AUTOSAR XML (schema 4-3-0)
standard types defined: boolean, uint8, boolean_CompuMethod, boolean_DataConstr, uint8_DataConstr
package /ComponentTypes/HkmcDiagSWC
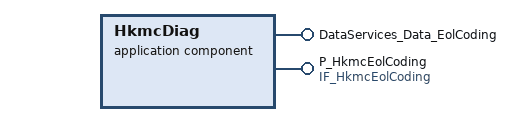
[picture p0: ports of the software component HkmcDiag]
  application sw component type HkmcDiag
    provide port DataServices_Data_EolCoding: provided-interface=DataServices_Data_EolCoding
      provided-com-specs:
        operation=ConditionCheckRead, queue-length=1
        operation=ReadData, queue-length=1
        operation=WriteData, queue-length=1
    provide port P_HkmcEolCoding: provided-com-specs=[{operation=HkmcEolCodingRead, queue-length=1}, {operation=HkmcEolCodingWrite, queue-length=1}], provided-interface=IF_HkmcEolCoding
    behavior HkmcDiag_InternalBehavior
      operation invoked event OIT_DataServices_Data_EolCoding_ConditionCheckRead_DataServices_Data_EolCoding_ConditionCheckRead: start-on-event=DataServices_Data_EolCoding_ConditionCheckRead, operation=DataServices_Data_EolCoding.ConditionCheckRead
      operation invoked event OIT_DataServices_Data_EolCoding_ReadData_DataServices_Data_EolCoding_ReadData: start-on-event=DataServices_Data_EolCoding_ReadData, operation=DataServices_Data_EolCoding.ReadData
      operation invoked event OIT_DataServices_Data_EolCoding_WriteData_DataServices_Data_EolCoding_WriteData: start-on-event=DataServices_Data_EolCoding_WriteData, operation=DataServices_Data_EolCoding.WriteData
      init event HkmcDiag_InitEvent: start-on-event=HkmcDiag_Init
      operation invoked event OIT_P_HkmcEolCoding_HkmcEolCodingRead_P_HkmcEolCoding_HkmcEolCodingRead: start-on-event=P_HkmcEolCoding_HkmcEolCodingRead, operation=P_HkmcEolCoding.HkmcEolCodingRead
      operation invoked event OIT_P_HkmcEolCoding_HkmcEolCodingWrite_P_HkmcEolCoding_HkmcEolCodingWrite: start-on-event=P_HkmcEolCoding_HkmcEolCodingWrite, operation=P_HkmcEolCoding.HkmcEolCodingWrite
      6 x runnable:
        DataServices_Data_EolCoding_ConditionCheckRead
        DataServices_Data_EolCoding_ReadData
        DataServices_Data_EolCoding_WriteData
        HkmcDiag_Init
        P_HkmcEolCoding_HkmcEolCodingRead
        P_HkmcEolCoding_HkmcEolCodingWrite
  swc implementation HkmcDiag_Implementation: behavior=HkmcDiag_InternalBehavior
    code-descriptors:
      code Default: artifact-descriptors=autosar-engineering-object={short-label=Default, category=SWSRC}
package /ComponentTypes/HkmcDiagSWC/DataTypes
  impl type HkmcEolData: category=STRUCTURE, type-emitter=RTE
    8 x element, all with category=TYPE_REFERENCE, implementation-data-type=uint8:
      data{1..8}
package /ComponentTypes/HkmcDiagSWC/PortInterfaces
  client server interface IF_HkmcEolCoding: is-service=true
    operation HkmcEolCodingRead
      arg EolDataIn: type=HkmcEolData, direction=IN, server-argument-impl-policy=USE-ARGUMENT-TYPE
      arg ReadStatus: type=boolean, direction=OUT, server-argument-impl-policy=USE-ARGUMENT-TYPE
    operation HkmcEolCodingWrite
      arg EolDataIn: type=HkmcEolData, direction=IN, server-argument-impl-policy=USE-ARGUMENT-TYPE
      arg WriteStatus: type=boolean, direction=OUT, server-argument-impl-policy=USE-ARGUMENT-TYPE
package /MICROSAR/Dcm_swc/DataTypes
  impl type Dcm_Data8ByteType: category=ARRAY, sw-calibration-access=READ-ONLY
    element Dcm_Data8ByteTypeElement: array-size=8, array-size-semantics=FIXED-SIZE, implementation-data-type=uint8
  impl type Dcm_NegativeResponseCodeType:
    compu {0=DCM_E_POSITIVERESPONSE, 16=DCM_E_GENERALREJECT, 17=DCM_E_SERVICENOTSUPPORTED, 18=DCM_E_SUBFUNCTIONNOTSUPPORTED, 19=DCM_E_INCORRECTMESSAGELENGTHORINVALIDFORMAT, 20=DCM_E_RESPONSETOOLONG, 33=DCM_E_BUSYREPEATREQUEST, 34=DCM_E_CONDITIONSNOTCORRECT, 36=DCM_E_REQUESTSEQUENCEERROR, 37=DCM_E_NORESPONSEFROMSUBNETCOMPONENT, 38=DCM_E_FAILUREPREVENTSEXECUTIONOFREQUESTEDACTION, 49=DCM_E_REQUESTOUTOFRANGE, 51=DCM_E_SECURITYACCESSDENIED, 53=DCM_E_INVALIDKEY, 54=DCM_E_EXCEEDNUMBEROFATTEMPTS, 55=DCM_E_REQUIREDTIMEDELAYNOTEXPIRED, 112=DCM_E_UPLOADDOWNLOADNOTACCEPTED, 113=DCM_E_TRANSFERDATASUSPENDED, 114=DCM_E_GENERALPROGRAMMINGFAILURE, 115=DCM_E_WRONGBLOCKSEQUENCECOUNTER, 120=DCM_E_REQUESTCORRECTLYRECEIVEDRESPONSEPENDING, 126=DCM_E_SUBFUNCTIONNOTSUPPORTEDINACTIVESESSION, 127=DCM_E_SERVICENOTSUPPORTEDINACTIVESESSION, 129=DCM_E_RPMTOOHIGH, 130=DCM_E_RPMTOOLOW, 131=DCM_E_ENGINEISRUNNING, 132=DCM_E_ENGINEISNOTRUNNING, 133=DCM_E_ENGINERUNTIMETOOLOW, 134=DCM_E_TEMPERATURETOOHIGH, 135=DCM_E_TEMPERATURETOOLOW, 136=DCM_E_VEHICLESPEEDTOOHIGH, 137=DCM_E_VEHICLESPEEDTOOLOW, 138=DCM_E_THROTTLE_PEDALTOOHIGH, 139=DCM_E_THROTTLE_PEDALTOOLOW, 140=DCM_E_TRANSMISSIONRANGENOTINNEUTRAL, 141=DCM_E_TRANSMISSIONRANGENOTINGEAR, 143=DCM_E_BRAKESWITCH_NOTCLOSED, 144=DCM_E_SHIFTERLEVERNOTINPARK, 145=DCM_E_TORQUECONVERTERCLUTCHLOCKED, 146=DCM_E_VOLTAGETOOHIGH, 147=DCM_E_VOLTAGETOOLOW, 240..249=DCM_E_VMSCNC_0..DCM_E_VMSCNC_9, 250=DCM_E_VMSCNC_A, 251=DCM_E_VMSCNC_B, 252=DCM_E_VMSCNC_C, 253=DCM_E_VMSCNC_D, 254=DCM_E_VMSCNC_E}
    range raw 0..254
    implementation-data-type=uint8
  impl type Dcm_OpStatusType: compu {0=DCM_INITIAL, 1=DCM_PENDING, 2=DCM_CANCEL, 3=DCM_FORCE_RCRRP_OK, 64=DCM_FORCE_RCRRP_NOT_OK}, range raw 0..64, implementation-data-type=uint8
package /MICROSAR/Dcm_swc/Interfaces
  client server interface DataServices_Data_EolCoding: is-service=true, service-kind=DIAGNOSTIC-COMMUNICATION-MANAGER
    operation ConditionCheckRead: possible-error=[DCM_E_PENDING, E_NOT_OK]
      arg OpStatus: type=Dcm_OpStatusType, direction=IN, server-argument-impl-policy=USE-ARGUMENT-TYPE
      arg ErrorCode: type=Dcm_NegativeResponseCodeType, direction=OUT, server-argument-impl-policy=USE-ARGUMENT-TYPE
    operation ReadData: possible-error=[DCM_E_PENDING, E_NOT_OK]
      arg OpStatus: type=Dcm_OpStatusType, direction=IN, server-argument-impl-policy=USE-ARGUMENT-TYPE
      arg Data: type=Dcm_Data8ByteType, direction=OUT, server-argument-impl-policy=USE-ARGUMENT-TYPE
    operation WriteData: possible-error=[DCM_E_PENDING, E_NOT_OK]
      arg Data: type=Dcm_Data8ByteType, direction=IN, server-argument-impl-policy=USE-ARGUMENT-TYPE
      arg OpStatus: type=Dcm_OpStatusType, direction=IN, server-argument-impl-policy=USE-ARGUMENT-TYPE
      arg ErrorCode: type=Dcm_NegativeResponseCodeType, direction=OUT, server-argument-impl-policy=USE-ARGUMENT-TYPE
    error DCM_E_PENDING: error-code=10
    error E_NOT_OK: error-code=1
